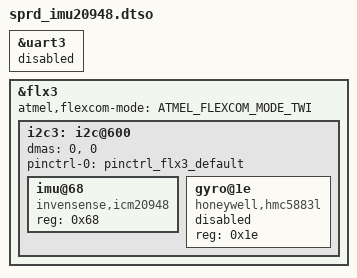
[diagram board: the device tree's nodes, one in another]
// SPDX-License-Identifier: (GPL-2.0+ OR MIT)

/dts-v1/;
/plugin/;

#include <dt-bindings/mfd/atmel-flexcom.h>

&uart3 {
	status = "disabled";
};

&flx3 {
	atmel,flexcom-mode = <ATMEL_FLEXCOM_MODE_TWI>;
	status = "okay";

	i2c3: i2c@600 {
		#address-cells = <1>;
		#size-cells = <0>;
		dmas = <0>, <0>;
		pinctrl-names = "default";
		pinctrl-0 = <&pinctrl_flx3_default>;
		status = "okay";

		imu@68 {
			compatible = "invensense,icm20948";
			reg = <0x68>;
			status = "okay";
		};

		gyro@1e {
			compatible = "honeywell,hmc5883l";
			reg = <0x1e>;
			status = "disabled";
		};

	};
};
